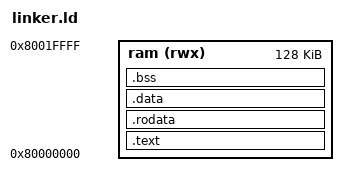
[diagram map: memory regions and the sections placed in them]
OUTPUT_ARCH(riscv)
ENTRY(_start)

MEMORY
{
  ram (rwx) : ORIGIN = 0x80000000, LENGTH = 128K
}

SECTIONS
{
  .text : {
    *(.text.init)
    *(.text*)
  } > ram

  .rodata : {
    *(.rodata*)
  } > ram

  .data : {
    *(.data*)
  } > ram

  .bss : {
    *(.bss*)
    *(COMMON)
  } > ram

  . = ALIGN(16);
  . = ORIGIN(ram) + LENGTH(ram);
  _stack_top = .;
}
